# RZN1_MATRIX register map
Registers from a debugger description file.
Registers are 32-bit, access not given, no defined reset value unless marked. A register's access mark holds for its fields unless they carry their own. Addresses are absolute; registers are grouped by the start of their names; lines under a group give offsets from that group; [hi:lo] are bit positions; {n}, {i} and the like mark numbered series; 'fields as' and 'values as' point back to an identical list; <NAME> marks a mode.

## Id
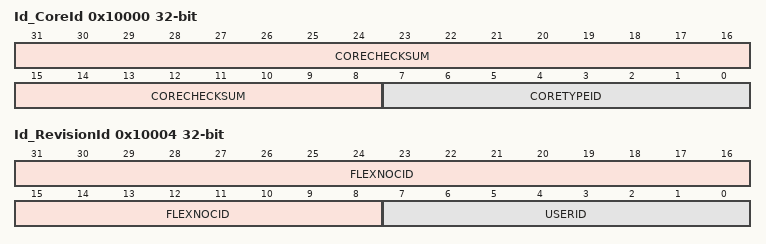
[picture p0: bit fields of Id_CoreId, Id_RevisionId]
0x10000 Id_CoreId
  [31:8] CORECHECKSUM, [7:0] CORETYPEID
0x10004 Id_RevisionId
  [31:8] FLEXNOCID, [7:0] USERID

## SFR
0x10008 FaultEn
  [0] FAULTEN
0x1000C ErrVld
  [0] ERRVLD
0x10010 ErrClr
  [0] ERRCLR
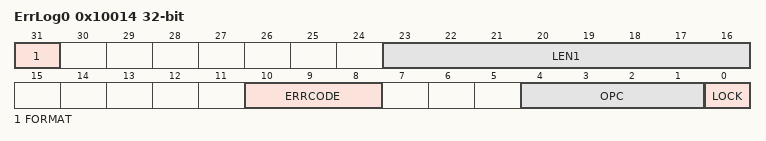
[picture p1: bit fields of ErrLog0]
0x10014 ErrLog0
  [31] FORMAT, [23:16] LEN1, [10:8] ERRCODE, [4:1] OPC, [0] LOCK
0x10018 ErrLog1
  [19:0] ERRLOG1
0x10020 ErrLog3
  [30:0] ERRLOG3
0x10028 ErrLog5
  [8:0] ERRLOG5
